# LIS331EB register map
Vendor: STMicroelectronics; Series: LIS331EB; File version: 1.0
CPU: CM0 r0p0, little endian, no MPU, no FPU, 5 interrupt priority bits
Registers are 32-bit, read-write, reset 0x0 unless marked. A register's access mark holds for its fields unless they carry their own. Offsets are from the block's base; [hi:lo] are bit positions; {n}, {i} and the like mark numbered series.

## SPI1 — PrimeCell Synchronous Serial Port (PL022)
Base 0xA3000000
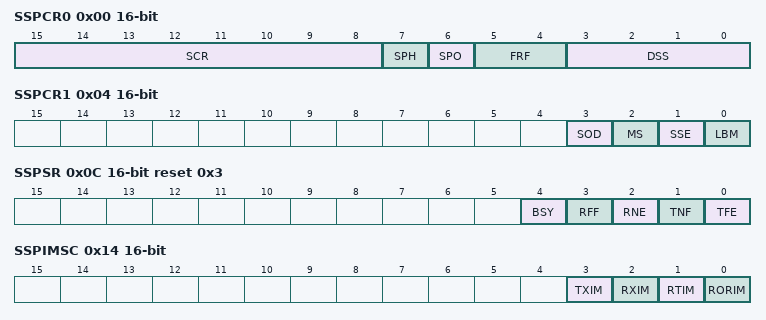
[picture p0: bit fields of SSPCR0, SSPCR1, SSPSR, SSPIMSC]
0x00 SSPCR0 16-bit — Control Register 0
  [15:8] SCR — Serial Clock Rate
  [7] SPH — SSPCLKOUT phase
  [6] SPO — SSPCLKOUT polarity
  [5:4] FRF — Frame Format
    0=Motorola SPI frame format; 1=TI (TI synchronous serial frame format); 2=National Microwire frame format
  [3:0] DSS — Data Size Select
    {v}={v+1}-bit data (v=3..15)
0x04 SSPCR1 16-bit — Control Register 1
  [3] SOD — Slave-mode output disable
  [2] MS — Master or slave mode select
    0=Master mode; 1=Slave mode
  [1] SSE — Synchronous serial port enable
  [0] LBM — Loopback mode
0x08 SSPDR 16-bit — Data Register
  [15:0] DATA — Transmit/Receive FIFO
0x0C SSPSR 16-bit ro reset 0x3 — Status Register
  [4] BSY — PrimeCell SSP busy flag
  [3] RFF — Receive FIFO full
  [2] RNE — Receive FIFO not empty
  [1] TNF — Transmit FIFO not full
  [0] TFE — Transmit FIFO empty
0x10 SSPCPSR 16-bit — Clock prescale register
  [7:0] CPSDVSR range 2..254 — Clock prescale divisor
0x14 SSPIMSC 16-bit — Interrupt Mask Set or Clear Register
  [3] TXIM — Transmit FIFO interrupt mask
  [2] RXIM — Receive FIFO interrupt mask
  [1] RTIM — Receive timeout interrupt mask
  [0] RORIM — Receive overrun interrupt mask
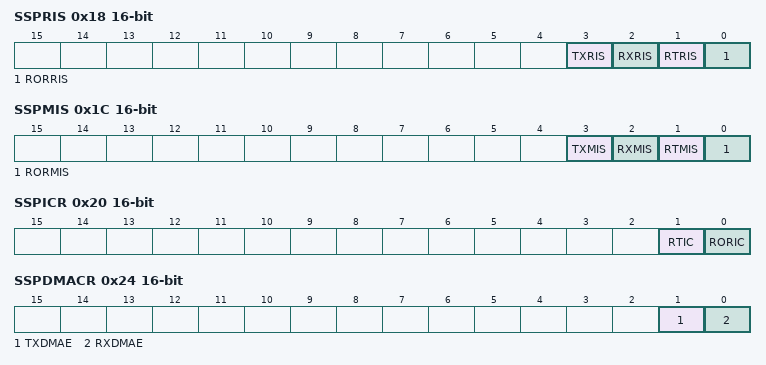
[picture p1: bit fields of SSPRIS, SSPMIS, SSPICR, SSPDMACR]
0x18 SSPRIS 16-bit ro — Raw Interrupt Status Register
  [3] TXRIS — Gives the raw interrupt state, prior to masking, of the SSPTXINTR interrupt
  [2] RXRIS — Gives the raw interrupt state, prior to masking, of the SSPRXINTR interrupt
  [1] RTRIS — Gives the raw interrupt state, prior to masking, of the SSPRTINTR interrupt
  [0] RORRIS — Gives the raw interrupt state, prior to masking, of the SSPRORINTR interrupt
0x1C SSPMIS 16-bit ro — Masked Interrupt Status Register
  [3] TXMIS — Gives the transmit FIFO masked interrupt state, after masking, of the SSPTXINTR interrupt
  [2] RXMIS — Gives the receive FIFO masked interrupt state, after masking, of the SSPRXINTR interrupt
  [1] RTMIS — Gives the receive timeout masked interrupt state, after masking, of the SSPRTINTR interrupt
  [0] RORMIS — Gives the receive over run masked interrupt status, after masking, of the SSPRORINTR interrupt
0x20 SSPICR 16-bit wo — Interrupt clear register
  [1] RTIC — Clears the SSPRTINTR interrupt
  [0] RORIC — Clears the SSPRORINTR interrupt
0x24 SSPDMACR 16-bit — DMA control register
  [1] TXDMAE — Transmit DMA Enable
  [0] RXDMAE — Receive DMA Enable
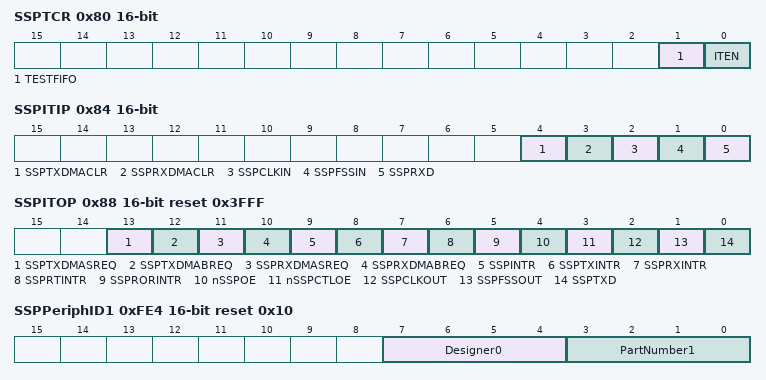
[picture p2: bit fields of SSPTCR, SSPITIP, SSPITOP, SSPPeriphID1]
0x80 SSPTCR 16-bit — Test Control Register
  [1] TESTFIFO — Test FIFO enable
  [0] ITEN — Integration test enable
0x84 SSPITIP 16-bit — Integration Test Input Register
  [4] SSPTXDMACLR — Writes to this bit specify the value to be driven on the intra-chip input, SSPTXDMACLR, in the integration test mode. Reads return the value of SSPTXDMACLR at the output of the test multiplexor
  [3] SSPRXDMACLR — Writes to this bit specify the value to be driven on the intra-chip input, SSPRXDMACLR, in the integration test mode. Reads return the value of SSPRXDMACLR at the output of the test multiplexor
  [2] SSPCLKIN — Reads return the value of the SSPCLKIN primary input
  [1] SSPFSSIN — Reads return the value of the SSPFSSIN primary input
  [0] SSPRXD — Reads return the value of the SSPRXD primary input
0x88 SSPITOP 16-bit reset 0x3FFF (reset mask 0x0) — Integration Test Output Register
  [13] SSPTXDMASREQ — Writes specify the value to be driven on the SSPTXDMASREQ line in the integration test mode. Reads return the value of SSPTXDMASREQ at the output of the test multiplexor
  [12] SSPTXDMABREQ — Writes specify the value to be driven on the SSPTXDMABREQ line in the integration test mode. Reads return the value of SSPTXDMABREQ at the output of the test multiplexor
  [11] SSPRXDMASREQ — Writes specify the value to be driven on the SSPRXDMASREQ line in the integration test mode. Reads return the value of SSPRXDMASREQ at the output of the test multiplexor
  [10] SSPRXDMABREQ — Writes specify the value to be driven on the SSPRXDMABREQ line in the integration test mode. Reads return the value of SSPRXDMABREQ at the output of the test multiplexor
  [9] SSPINTR — Writes specify the value to be driven on the SSPINTR line in the integration test mode. Reads return the value of SSPINTR at the output of the test multiplexor
  [8] SSPTXINTR — Writes specify the value to be driven on the SSPTXINTR line in the integration test mode. Reads return the value of SSPTXINTR at the output of the test multiplexor
  [7] SSPRXINTR — Writes specify the value to be driven on the SSPRXINTR line in the integration test mode. Reads return the value of SSPRXINTR at the output of the test multiplexor
  [6] SSPRTINTR — Writes specify the value to be driven on the SSPRTINTR line in the integration test mode. Reads return the value of SSPRTINTR at the output of the test multiplexor
  [5] SSPRORINTR — Writes specify the value to be driven on the SSPRORINTR line in the integration test mode. Reads return the value of SSPRORINTR at the output of the test multiplexor
  [4] nSSPOE — Writes specify the value to be driven on the nSSPOE line in the integration test mode
  [3] nSSPCTLOE — Writes specify the value to be driven on the nSSPCTLOE line in the integration test mode
  [2] SSPCLKOUT — Writes specify the value to be driven on the SSPCLKOUT line in the integration test mode
  [1] SSPFSSOUT — Writes specify the value to be driven on the SSPFSSOUT line in the integration test mode
  [0] SSPTXD — Writes specify the value to be driven on the SSPTXD line in the integration test mode
0x8C SSPTDR 16-bit reset 0xFFFF (reset mask 0x0) — Test Data Register
  [15:0] DATA — When the TESTFIFO signal is asserted, data is written into the receive FIFO and read out of the transmit FIFO
0xFE0 SSPPeriphID0 16-bit ro reset 0x22
  [7:0] PartNumber0 — These bits read back as 0x22
0xFE4 SSPPeriphID1 16-bit ro reset 0x10
  [7:4] Designer0 — These bits read back as 0x1
  [3:0] PartNumber1 — These bits read back as 0x0
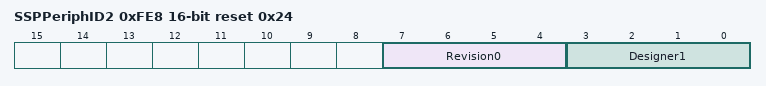
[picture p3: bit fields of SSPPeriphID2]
0xFE8 SSPPeriphID2 16-bit ro reset 0x24
  [7:4] Revision0 — These bits read back as 0x2
  [3:0] Designer1 — These bits read back as 0x4
0xFEC SSPPeriphID3 16-bit ro
  [7:0] Configuration — These bits read back as 0x00
0xFF0 SSPPCellID0 16-bit ro reset 0xD
  [7:0] SSPPCellID0 — These bits read back as 0x0D
0xFF4 SSPPCellID1 16-bit ro reset 0xF0
  [7:0] SSPPCellID1 — These bits read back as 0xF0
0xFF8 SSPPCellID2 16-bit ro reset 0x5
  [7:0] SSPPCellID2 — These bits read back as 0x05
0xFFC SSPPCellID3 16-bit ro reset 0xB1
  [7:0] SSPPCellID3 — These bits read back as 0xB1
